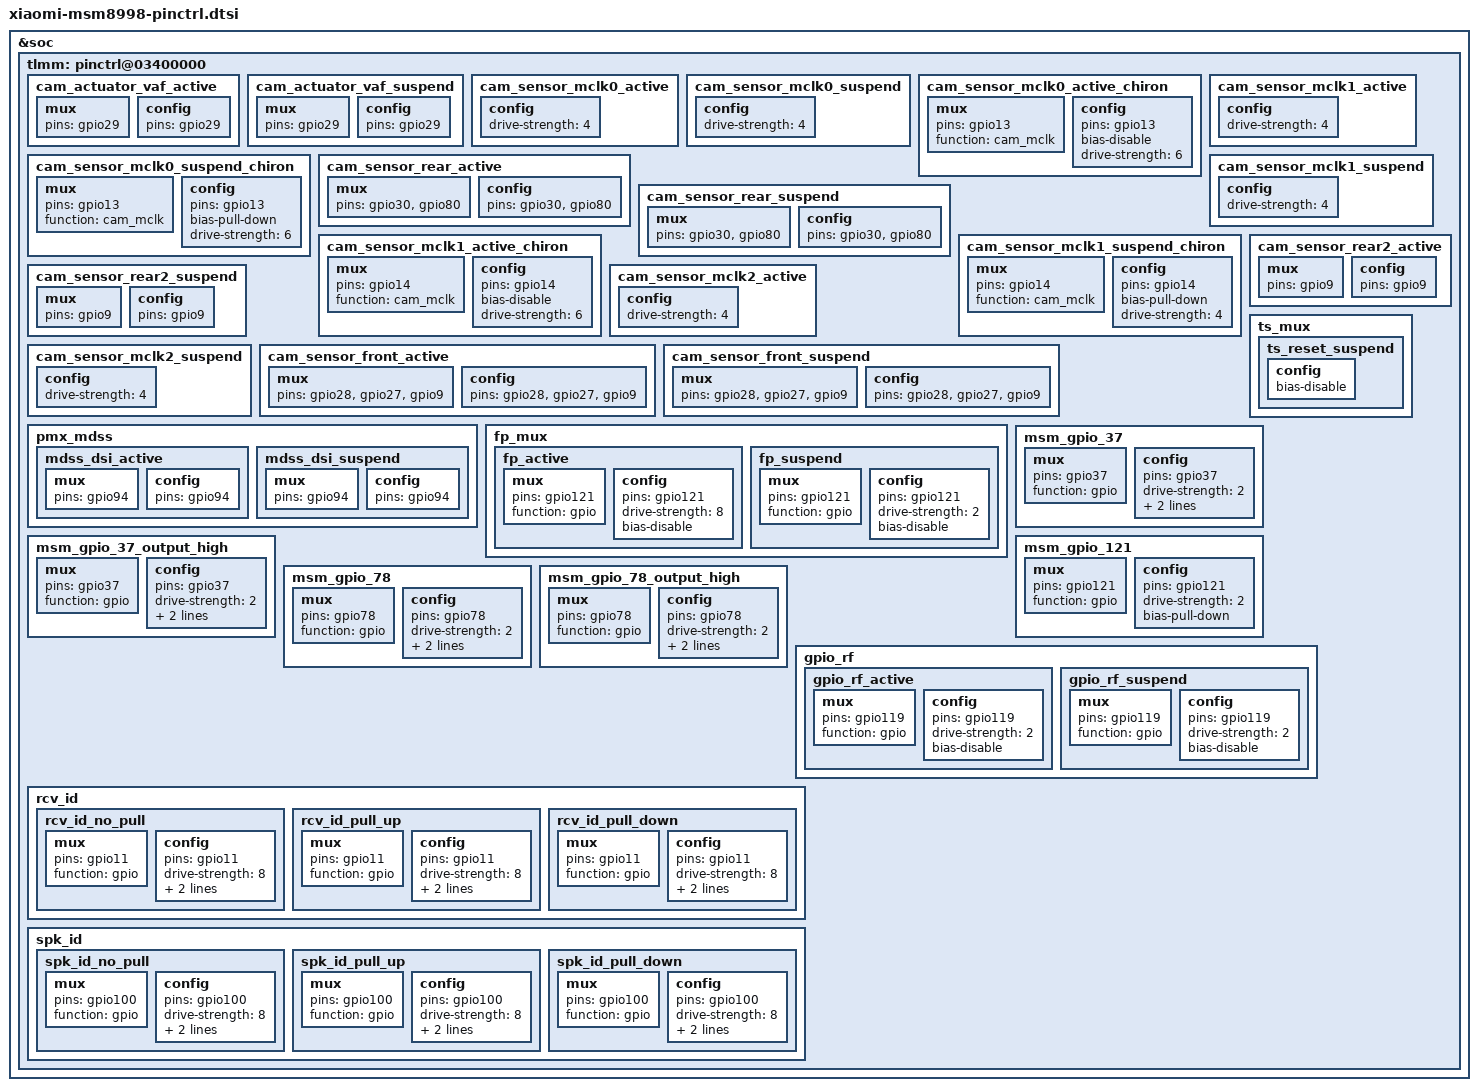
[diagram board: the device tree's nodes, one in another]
/* Copyright (c) 2015-2017, The Linux Foundation. All rights reserved.
 * Copyright (C) 2017 XiaoMi, Inc.
 *
 * This program is free software; you can redistribute it and/or modify
 * it under the terms of the GNU General Public License version 2 and
 * only version 2 as published by the Free Software Foundation.
 *
 * This program is distributed in the hope that it will be useful,
 * but WITHOUT ANY WARRANTY; without even the implied warranty of
 * MERCHANTABILITY or FITNESS FOR A PARTICULAR PURPOSE.  See the
 * GNU General Public License for more details.
 */

&soc {
	tlmm: pinctrl@03400000 {
		cam_actuator_vaf_active: cam_actuator_vaf_active {
			/* ACTUATOR POWER */
			mux {
				pins = "gpio29";
			};

			config {
				pins = "gpio29";
			};
		};

		cam_actuator_vaf_suspend: cam_actuator_vaf_suspend {
			/* ACTUATOR POWER */
			mux {
				pins = "gpio29";
			};

			config {
				pins = "gpio29";
			};
		};

		cam_sensor_mclk0_active: cam_sensor_mclk0_active {
			/* MCLK0 */
			config {
				drive-strength = <4>; /* 2 MA */
			};
		};

		cam_sensor_mclk0_suspend: cam_sensor_mclk0_suspend {
			config {
				drive-strength = <4>; /* 2 MA */
			};
		};

		cam_sensor_mclk0_active_chiron: cam_sensor_mclk0_active_chiron {
			/* MCLK0 */
			mux {
				/* CLK */
				pins = "gpio13";
				function = "cam_mclk";
			};

			config {
				pins = "gpio13";
				bias-disable; /* No PULL */
				drive-strength = <6>; /* 2 MA */
			};
		};

		cam_sensor_mclk0_suspend_chiron: cam_sensor_mclk0_suspend_chiron {
			/* MCLK0 */
			mux {
				/* CLK */
				pins = "gpio13";
				function = "cam_mclk";
			};

			config {
				pins = "gpio13";
				bias-pull-down; /* PULL DOWN */
				drive-strength = <6>; /* 2 MA */
			};
		};

		cam_sensor_rear_active: cam_sensor_rear_active {
			/* RESET, STANDBY */
			mux {
				pins = "gpio30", "gpio80";
			};

			config {
				pins = "gpio30", "gpio80";
			};
		};

		cam_sensor_rear_suspend: cam_sensor_rear_suspend {
			/* RESET, STANDBY */
			mux {
				pins = "gpio30","gpio80";
			};

			config {
				pins = "gpio30","gpio80";
			};
		};

		cam_sensor_mclk1_active: cam_sensor_mclk1_active {
			/* MCLK1 */
			config {
				drive-strength = <4>; /* 2 MA */
			};
		};

		cam_sensor_mclk1_suspend: cam_sensor_mclk1_suspend {
			/* MCLK1 */
			config {
				drive-strength = <4>; /* 2 MA */
			};
		};

		cam_sensor_mclk1_active_chiron: cam_sensor_mclk1_active_chiron {
		/* MCLK1 */
			mux {
			/* CLK */
				pins = "gpio14";
				function = "cam_mclk";
			};

			config {
				pins = "gpio14";
				bias-disable; /* No PULL */
				drive-strength = <6>; /* 2 MA */
			};
		};

		cam_sensor_mclk1_suspend_chiron: cam_sensor_mclk1_suspend_chiron {
			/* MCLK1 */
			mux {
			/* CLK */
				pins = "gpio14";
				function = "cam_mclk";
			};

			config {
				pins = "gpio14";
				bias-pull-down; /* PULL DOWN */
				drive-strength = <4>; /* 2 MA */
			};
		};

		cam_sensor_rear2_active: cam_sensor_rear2_active {
			/* RESET, STANDBY */
			mux {
				pins = "gpio9";
			};

			config {
				pins = "gpio9";
			};
		};

		cam_sensor_rear2_suspend: cam_sensor_rear2_suspend {
			/* RESET, STANDBY */
			mux {
				pins = "gpio9";
			};
			config {
				pins = "gpio9";
			};
		};

		cam_sensor_mclk2_active: cam_sensor_mclk2_active {
			/* MCLK1 */
			config {
				drive-strength = <4>; /* 2 MA */
			};
		};

		cam_sensor_mclk2_suspend: cam_sensor_mclk2_suspend {
			/* MCLK1 */
			config {
				drive-strength = <4>; /* 2 MA */
			};
		};

		cam_sensor_front_active: cam_sensor_front_active {
			/* RESET  VANA*/
			mux {
				pins = "gpio28", "gpio27","gpio9";
			};

			config {
				pins = "gpio28", "gpio27","gpio9";
			};
		};

		cam_sensor_front_suspend: cam_sensor_front_suspend {
			/* RESET */
			mux {
				pins = "gpio28", "gpio27","gpio9";
			};

			config {
				pins = "gpio28", "gpio27","gpio9";
			};
		};

		pmx_mdss: pmx_mdss {
			mdss_dsi_active: mdss_dsi_active {
				mux {
					pins = "gpio94";
				};

				config {
					pins = "gpio94";
				};
			};
			mdss_dsi_suspend: mdss_dsi_suspend {
				mux {
					pins = "gpio94";
				};

				config {
					pins = "gpio94";
				};
			};
		};

		ts_mux {
			ts_reset_suspend: ts_reset_suspend {
				config {
					/delete-property/ bias-pull-down;
					bias-disable;
				};
			};
		};

		fp_mux {
			fp_active: fp_active {
				mux {
					pins = "gpio121";
					function = "gpio";
				};
				config {
					pins = "gpio121";
					drive-strength = <8>;
					bias-disable;
				};
			};

			fp_suspend: fp_suspend {
				mux {
					pins = "gpio121";
					function = "gpio";
				};
				config {
					pins = "gpio121";
					drive-strength = <2>;
					bias-disable;
				};
			};
		};
		msm_gpio_37: msm_gpio_37 {
			mux {
				 pins = "gpio37";
				 function = "gpio";
			};

			config {
				pins = "gpio37";
				drive-strength = <2>;
				bias-disable;
				output-low;
			};
		};

		msm_gpio_37_output_high: msm_gpio_37_output_high {
			mux {
				pins = "gpio37";
				function = "gpio";
			};

			config {
				pins = "gpio37";
				drive-strength = <2>;
				bias-disable;
				output-high;
			};
		};

		msm_gpio_121: msm_gpio_121 {
			mux {
				pins = "gpio121";
				function = "gpio";
			};

			config {
				pins = "gpio121";
				drive-strength = <2>;
				bias-pull-down;
			};
		};

		msm_gpio_78: msm_gpio_78 {
			mux {
				 pins = "gpio78";
				 function = "gpio";
			};

			config {
				pins = "gpio78";
				drive-strength = <2>;
				bias-disable;
				output-low;
			};
		};

		msm_gpio_78_output_high: msm_gpio_78_output_high {
			mux {
				pins = "gpio78";
				function = "gpio";
			};

			config {
				pins = "gpio78";
				drive-strength = <2>;
				bias-disable;
				output-high;
			};
		};

		gpio_rf {
			gpio_rf_active: gpio_rf_active {
				mux {
					pins = "gpio119";
					function = "gpio";
				};
				config {
					pins = "gpio119";
					drive-strength = <2>;
					bias-disable;
				};
			};
			 gpio_rf_suspend: gpio_rf_suspend {
				mux {
					pins = "gpio119";
					function = "gpio";
				};
				config {
					pins = "gpio119";
					drive-strength = <2>;
					bias-disable;
				};
			};
		};

		rcv_id {
			rcv_id_no_pull: rcv_id_no_pull {
				mux {
					pins = "gpio11";
					function = "gpio";
				};
				config {
					pins = "gpio11";
					drive-strength = <8>;
					bias-disable;
					input-enable;
				};
			};
			rcv_id_pull_up: rcv_id_pull_up {
				mux {
					pins = "gpio11";
					function = "gpio";
				};
				config {
					pins = "gpio11";
					drive-strength = <8>;
					bias-pull-up;
					input-enable;
				};
			};
			rcv_id_pull_down: rcv_id_pull_down {
				mux {
					pins = "gpio11";
					function = "gpio";
				};
				config {
					pins = "gpio11";
					drive-strength = <8>;
					bias-pull-down;
					input-enable;
				};
			};
		};

		spk_id {
			spk_id_no_pull: spk_id_no_pull {
				mux {
					pins = "gpio100";
					function = "gpio";
				};
				config {
					pins = "gpio100";
					drive-strength = <8>;
					bias-disable;
					input-enable;
				};
			};
			spk_id_pull_up: spk_id_pull_up {
				mux {
					pins = "gpio100";
					function = "gpio";
				};
				config {
					pins = "gpio100";
					drive-strength = <8>;
					bias-pull-up;
					input-enable;
				};
			};
			spk_id_pull_down: spk_id_pull_down {
				mux {
					pins = "gpio100";
					function = "gpio";
				};
				config {
					pins = "gpio100";
					drive-strength = <8>;
					bias-pull-down;
					input-enable;
				};
			};
		};
	};
};
